# ESP32 register map
Vendor: ESPRESSIF SYSTEMS (SHANGHAI) CO., LTD.; Series: ESP32 Series; File version: 17
CPU: Xtensa LX6 r0p0, little endian, no MPU, FPU, 0 interrupt priority bits
Address unit: 32 bits
Registers are 32-bit, read-write, reset 0x0 unless marked. A register's access mark holds for its fields unless they carry their own. Offsets are from the block's base; [hi:lo] are bit positions; {n}, {i} and the like mark numbered series; 'fields as' and 'values as' point back to an identical list.

## IO_MUX — Input/Output Multiplexer
Base 0x3FF49000
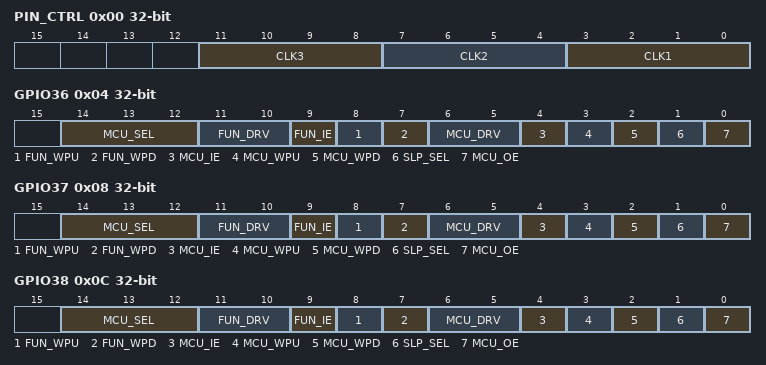
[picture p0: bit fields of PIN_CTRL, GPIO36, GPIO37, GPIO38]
0x00 PIN_CTRL
  [11:8] CLK3 — If you want to output clock for I2S0 to: CLK_OUT1, then set PIN_CTRL[3:0] = 0x0; CLK_OUT2, then set PIN_CTRL[3:0] = 0x0 and PIN_CTRL[7:4] = 0x0; CLK_OUT3, then set PIN_CTRL[3:0] = 0x0 and PIN_CTRL[11:8] = 0x0. If you want to output clock for I2S1 to: CLK_OUT1, then set PIN_CTRL[3:0] = 0xF; CLK_OUT2, then set PIN_CTRL[3:0] = 0xF and PIN_CTRL[7:4] = 0x0; CLK_OUT3, then set PIN_CTRL[3:0] = 0xF and PIN_CTRL[11:8] = 0x0.
  [7:4] CLK2 — If you want to output clock for I2S0 to: CLK_OUT1, then set PIN_CTRL[3:0] = 0x0; CLK_OUT2, then set PIN_CTRL[3:0] = 0x0 and PIN_CTRL[7:4] = 0x0; CLK_OUT3, then set PIN_CTRL[3:0] = 0x0 and PIN_CTRL[11:8] = 0x0. If you want to output clock for I2S1 to: CLK_OUT1, then set PIN_CTRL[3:0] = 0xF; CLK_OUT2, then set PIN_CTRL[3:0] = 0xF and PIN_CTRL[7:4] = 0x0; CLK_OUT3, then set PIN_CTRL[3:0] = 0xF and PIN_CTRL[11:8] = 0x0.
  [3:0] CLK1 — If you want to output clock for I2S0 to: CLK_OUT1, then set PIN_CTRL[3:0] = 0x0; CLK_OUT2, then set PIN_CTRL[3:0] = 0x0 and PIN_CTRL[7:4] = 0x0; CLK_OUT3, then set PIN_CTRL[3:0] = 0x0 and PIN_CTRL[11:8] = 0x0. If you want to output clock for I2S1 to: CLK_OUT1, then set PIN_CTRL[3:0] = 0xF; CLK_OUT2, then set PIN_CTRL[3:0] = 0xF and PIN_CTRL[7:4] = 0x0; CLK_OUT3, then set PIN_CTRL[3:0] = 0xF and PIN_CTRL[11:8] = 0x0.
0x04 GPIO36
  [14:12] MCU_SEL — Select the IO_MUX function for this signal. 0 selects Function 0, 1 selects Function 1, etc.
  [11:10] FUN_DRV — Select the drive strength of the pad. A higher value corresponds with a higher strength. For GPIO34-39, FUN_DRV is always 0. For detailed drive strength, please see note 8 in Table ”Notes on ESP32 Pin Lists”, in ESP32 Datasheet.
  [9] FUN_IE — Input enable of the pad. 1: input enabled; 0: input disabled.
  [8] FUN_WPU — Pull-up enable of the pad. 1: internal pull-up enabled; 0: internal pull-up disabled. GPIO pins 34-39 are input-only. These pins do not feature an output driver or internal pull- up/pull- down circuitry, therefore, their FUN_WPU is always 0.
  [7] FUN_WPD — Pull-down enable of the pad. 1: internal pull-down enabled, 0: internal pull-down disabled. GPIO pins 34-39 are input-only. These pins do not feature an output driver or internal pull- up/pull-down circuitry, therefore, their FUN_WPD is always 0.
  [6:5] MCU_DRV — Select the drive strength of the pad during sleep mode. A higher value corresponds with a higher strength.
  [4] MCU_IE — Input enable of the pad during sleep mode. 1: input enabled; 0: input disabled.
  [3] MCU_WPU — Pull-up enable of the pad during sleep mode. 1: internal pull-up enabled; 0: internal pull-up disabled.
  [2] MCU_WPD — Pull-down enable of the pad during sleep mode. 1: internal pull-down enabled; 0: internal pull-down disabled.
  [1] SLP_SEL — Sleep mode selection of this pad. Set to 1 to put the pad in sleep mode.
  [0] MCU_OE — Output enable of the pad in sleep mode. 1: enable output; 0: disable output.
0x08 GPIO37
  fields as GPIO36
0x0C GPIO38
  fields as GPIO36
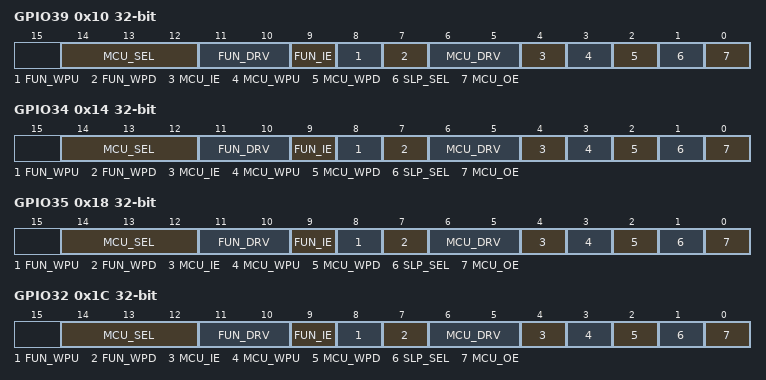
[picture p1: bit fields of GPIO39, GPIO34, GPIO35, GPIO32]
0x10 GPIO39
  fields as GPIO36
0x14 GPIO34
  fields as GPIO36
0x18 GPIO35
  fields as GPIO36
0x1C GPIO32
  fields as GPIO36
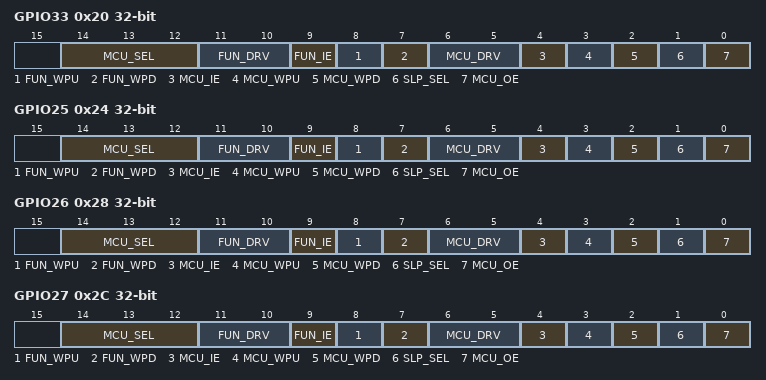
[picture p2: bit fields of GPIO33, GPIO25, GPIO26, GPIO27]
0x20 GPIO33
  fields as GPIO36
0x24 GPIO25
  fields as GPIO36
0x28 GPIO26
  fields as GPIO36
0x2C GPIO27
  fields as GPIO36
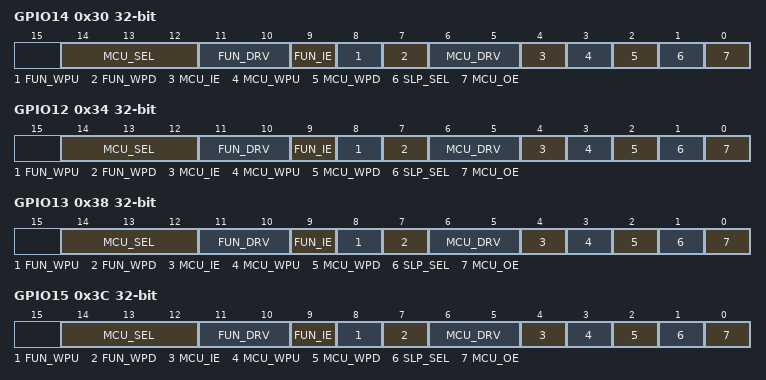
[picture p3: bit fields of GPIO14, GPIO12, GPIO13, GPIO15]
0x30 GPIO14
  fields as GPIO36
0x34 GPIO12
  fields as GPIO36
0x38 GPIO13
  fields as GPIO36
0x3C GPIO15
  fields as GPIO36
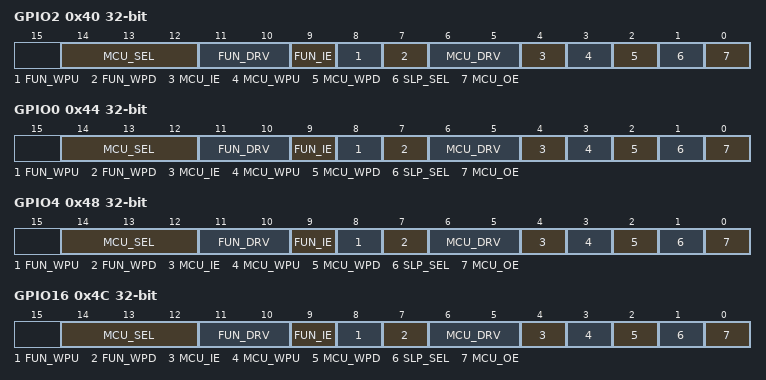
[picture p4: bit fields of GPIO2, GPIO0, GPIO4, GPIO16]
0x40 GPIO2
  fields as GPIO36
0x44 GPIO0
  fields as GPIO36
0x48 GPIO4
  fields as GPIO36
0x4C GPIO16
  fields as GPIO36
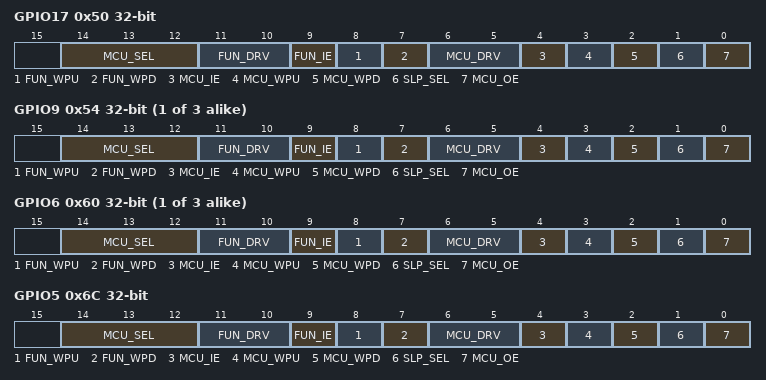
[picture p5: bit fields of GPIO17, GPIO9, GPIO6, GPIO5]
0x50 GPIO17
  fields as GPIO36
{0x30+4i} GPIO{i} (i=9..11)
  fields as GPIO36
{0x48+4i} GPIO{i} (i=6..8)
  fields as GPIO36
0x6C GPIO5
  fields as GPIO36
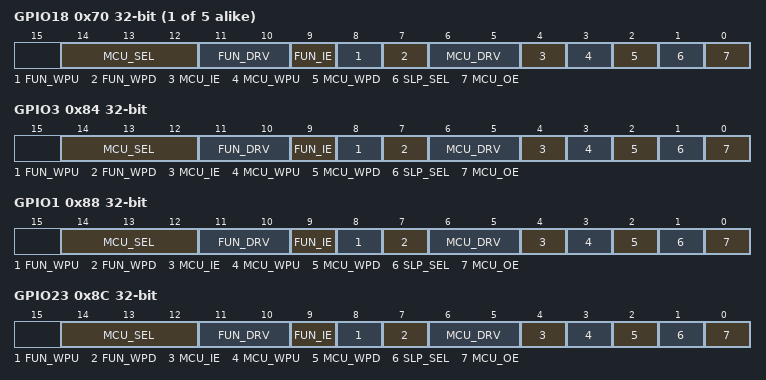
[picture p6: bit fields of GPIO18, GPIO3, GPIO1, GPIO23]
{0x28+4i} GPIO{i} (i=18..22)
  fields as GPIO36
0x84 GPIO3
  fields as GPIO36
0x88 GPIO1
  fields as GPIO36
0x8C GPIO23
  fields as GPIO36
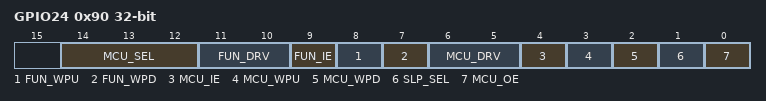
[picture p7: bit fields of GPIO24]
0x90 GPIO24
  fields as GPIO36
